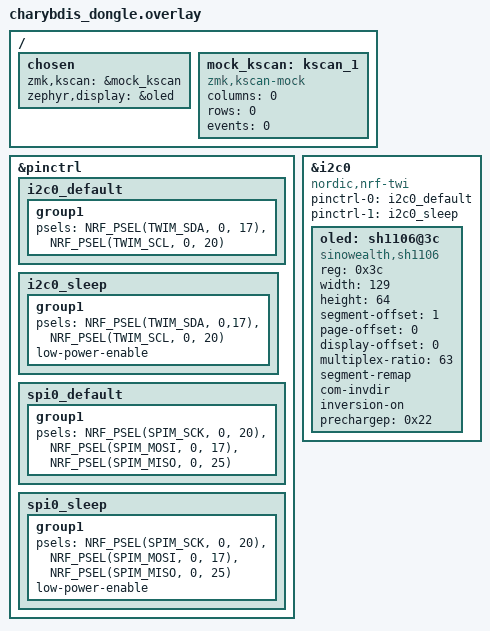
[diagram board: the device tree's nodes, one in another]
#include "charybdis.dtsi"

/delete-node/ &kscan0;


/ {
    chosen {
        zmk,kscan = &mock_kscan;
        zephyr,display = &oled;
    };

    mock_kscan: kscan_1 {
        compatible = "zmk,kscan-mock";
        columns = <0>;
        rows = <0>;
        events = <0>;
    };
};

&pinctrl {
    i2c0_default: i2c0_default {
        group1 {
            psels = <NRF_PSEL(TWIM_SDA, 0, 17)>,
                <NRF_PSEL(TWIM_SCL, 0, 20)>;
        };
    };

    i2c0_sleep: i2c0_sleep {
        group1 {
            psels = <NRF_PSEL(TWIM_SDA, 0,17)>,
                <NRF_PSEL(TWIM_SCL, 0, 20)>;
            low-power-enable;
        };
    };	
    
    spi0_default: spi0_default {
        group1 {
            psels = <NRF_PSEL(SPIM_SCK, 0, 20)>,
                <NRF_PSEL(SPIM_MOSI, 0, 17)>,
                <NRF_PSEL(SPIM_MISO, 0, 25)>;
        };
    };

    spi0_sleep: spi0_sleep {
        group1 {
            psels = <NRF_PSEL(SPIM_SCK, 0, 20)>,
                <NRF_PSEL(SPIM_MOSI, 0, 17)>,
                <NRF_PSEL(SPIM_MISO, 0, 25)>;
            low-power-enable;
        };
    };
};

&i2c0 {
	status = "okay";
	compatible = "nordic,nrf-twi";
    pinctrl-0 = <&i2c0_default>;
    pinctrl-1 = <&i2c0_sleep>;
	oled: sh1106@3c {
        compatible = "sinowealth,sh1106";
        reg = <0x3c>;
        width = <129>;
        height = <64>;
        segment-offset = <1>;
        page-offset = <0>;
        display-offset = <0>;
        multiplex-ratio = <63>;
        segment-remap;
        com-invdir;
        inversion-on;
        prechargep = <0x22>;
	};
};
